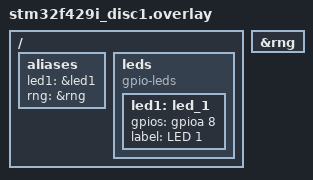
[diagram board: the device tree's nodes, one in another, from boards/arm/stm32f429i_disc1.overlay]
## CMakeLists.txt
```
cmake_minimum_required(VERSION 3.20.0)
find_package(Zephyr REQUIRED HINTS $ENV{ZEPHYR_BASE})

project(my_game_of_life)

# 1. Adiciona os arquivos fonte (.c) ao alvo 'app'

zephyr_include_directories(includes)
# 2. Diz ao CMake onde procurar o "shared_conf.h"
# (Assumindo que ele está na pasta src/ junto com os .c)

# Add all .c files inside src/
file(GLOB app_sources src/*.c)

target_sources(app PRIVATE ${app_sources})

target_include_directories(app PRIVATE src)
```

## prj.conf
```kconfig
# Habilitar Display e GPIO
CONFIG_DISPLAY=y
CONFIG_SPI=y
CONFIG_GPIO=y

# Habilitar LVGL (Biblioteca Gráfica)
#CONFIG_LVGL=y
CONFIG_LV_Z_MEM_POOL_SIZE=16384
CONFIG_LV_Z_SHELL=y
CONFIG_MAIN_STACK_SIZE=4096

# Buffer de desenho (Double Buffering recomendado para evitar flicker)
CONFIG_LV_Z_VDB_SIZE=10

# Suporte ao driver específico ILI9341 e LTDC
CONFIG_DISPLAY_LOG_LEVEL_ERR=y

# --- Geração de Números Aleatórios (Random) ---
# 1. Habilita o subsistema de entropia base
CONFIG_ENTROPY_GENERATOR=y

# 2. Habilita o driver de hardware do STM32
# (Isso vai funcionar agora graças ao seu arquivo .overlay corrigido)
CONFIG_ENTROPY_STM32_RNG=y

# 3. Diz ao Zephyr para usar o dispositivo de entropia como fonte para sys_rand_get()
# Esta é a opção que substitui as antigas CS_PRNG/SYS_RANDOM...
CONFIG_ENTROPY_DEVICE_RANDOM_GENERATOR=y

# --- Shell ---
CONFIG_SHELL=y
CONFIG_KERNEL_SHELL=y
CONFIG_SHELL_TAB_AUTOCOMPLETION=y

# --- Logging (caso use printk/LOG) ---
CONFIG_PRINTK=y
CONFIG_LOG=y
CONFIG_LOG_MODE_IMMEDIATE=y

# --- Threads / Workqueue ---
# Essencial para informações de runtime (uso de stack/pilha)
CONFIG_THREAD_MONITOR=y 
CONFIG_THREAD_NAME=y
CONFIG_SYSTEM_WORKQUEUE_STACK_SIZE=2048
CONFIG_SYSTEM_WORKQUEUE_PRIORITY=-1
# Habilita o subsistema de estatísticas de runtime
CONFIG_THREAD_RUNTIME_STATS=y 
# Permite a conversão de ciclos para milissegundos
CONFIG_SYS_CLOCK_TICKS_PER_SEC=1000

# --- UART (se usar terminal via UART) ---
CONFIG_UART_CONSOLE=y
```

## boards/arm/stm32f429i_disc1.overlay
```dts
#include <zephyr/dt-bindings/gpio/gpio.h>

/ {
	aliases {
		led1 = &led1;
        rng = &rng;
	};

	leds {
		compatible = "gpio-leds";
		led1: led_1 {
			gpios = <&gpioa 8 GPIO_ACTIVE_HIGH>; // Isso é porta 14 acho, tem que testar
			label = "LED 1";
		};
	};

};

&rng {
	status = "okay";
};
```

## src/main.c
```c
/*
 * Copyright (c) 2017 Linaro Limited
 *
 * SPDX-License-Identifier: Apache-2.0
 */

#include <zephyr/kernel.h>
#include <zephyr/device.h>
#include <zephyr/drivers/gpio.h>
#include <zephyr/sys/printk.h>
#include <zephyr/sys/__assert.h>

#include <string.h>
#include <terminal.h>

#define ZEPHYR_USER_NODE DT_PATH(zephyr_user)

/* size of stack area used by each thread */
#define STACKSIZE 1024

/* scheduling priority used by each thread */
#define PRIORITY 7

#define LED0_NODE DT_ALIAS(led0)
#define LED1_NODE DT_ALIAS(led1)

#if !DT_NODE_HAS_STATUS(LED0_NODE, okay)
#error "Unsupported board: led0 devicetree alias is not defined"
#endif


#if !DT_NODE_HAS_STATUS(LED1_NODE, okay)
#error "Unsupported board: led1 devicetree alias is not defined"
#endif

struct led {
	struct gpio_dt_spec spec;
	uint8_t num;
};

static const struct led led0 = {
	.spec = GPIO_DT_SPEC_GET_OR(LED0_NODE, gpios, {0}),
	.num = 0,
};


void blink(const struct led *led, uint32_t sleep_ms, uint32_t id)
{
	const struct gpio_dt_spec *spec = &led->spec;
	int ret;
	int cnt = 0;

	if (!device_is_ready(spec->port)) {
		printk("Error: %s device is not ready\n", spec->port->name);
		return;
	}

	ret = gpio_pin_configure_dt(spec, GPIO_OUTPUT);
	if (ret != 0) {
		printk("Error %d: failed to configure pin %d (LED '%d')\n",
			ret, spec->pin, led->num);
		return;
	}

	while (1) {
		gpio_pin_set(spec->port, spec->pin, cnt % 2);
		cnt++;

		k_msleep(sleep_ms);
	}
}

void blink0(void)
{
	blink(&led0, 200, 0);
}


K_THREAD_DEFINE(blink0_id, STACKSIZE, blink0, NULL, NULL, NULL,PRIORITY, 0, 0);
//k_thread_name_set(tid, "blink0");

int main(void)
{
    terminal_init();
    term_print("Shell ready. Try: echo, uptime, showdrop\n");

	return 0;
}
```

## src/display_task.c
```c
#include <shared_conf.h>
#include <zephyr/device.h>
#include <zephyr/drivers/display.h>
#include <string.h>

#define DISPLAY_PRIORITY 5
#define DISPLAY_STACK_SIZE 4096

static uint8_t frame_buffer[BUF_SIZE]; 

void draw_pixel(int x, int y, uint16_t color) {
    if (x < 0 || x >= SCREEN_WIDTH || y < 0 || y >= SCREEN_HEIGHT) return;
    
    int index = (y * SCREEN_WIDTH + x) * 2;
    frame_buffer[index] = color >> 8;     
    frame_buffer[index + 1] = color & 0xFF; 
}

void draw_cell(int grid_x, int grid_y, uint16_t color) {
    int start_x = grid_x * CELL_SIZE;
    int start_y = grid_y * CELL_SIZE;

    for (int y = 0; y < CELL_SIZE; y++) {
        for (int x = 0; x < CELL_SIZE; x++) {
            if (x < CELL_SIZE - 1 && y < CELL_SIZE - 1) {
                draw_pixel(start_x + x, start_y + y, color);
            }
        }
    }
}

// Função da Thread
void display_entry_point(void *p1, void *p2, void *p3) {
    const struct device *display_dev = DEVICE_DT_GET(DT_CHOSEN(zephyr_display));

    if (!device_is_ready(display_dev)) return;
    
    display_blanking_off(display_dev);

    struct display_buffer_descriptor desc;
    desc.buf_size = BUF_SIZE;
    desc.width = SCREEN_WIDTH;
    desc.height = SCREEN_HEIGHT;
    desc.pitch = SCREEN_WIDTH;

    while (1) {
        k_mutex_lock(&game_mutex, K_FOREVER);
        
        for (int y = 0; y < GRID_H; y++) {
            for (int x = 0; x < GRID_W; x++) {
                if (grid[y][x] == 1) {
                    draw_cell(x, y, COLOR_ALIVE);
                }else{
                    draw_cell(x, y, 0x0000);
                }
            }
        }
        
        k_mutex_unlock(&game_mutex);
        display_write(display_dev, 0, 0, &desc, frame_buffer);

        // Pequeno delay para evitar starvation
        k_sleep(K_MSEC(10)); 
    }
}

// Define e inicia a thread automaticamente no boot
K_THREAD_DEFINE(display_tid, DISPLAY_STACK_SIZE, display_entry_point, NULL, NULL, NULL,
                DISPLAY_PRIORITY, 0, 0);
```

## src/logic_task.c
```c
#include <shared_conf.h>
#include <zephyr/random/random.h>
#include <string.h>

// Definição das prioridades e stack
#define LOGIC_PRIORITY -1 // Alta prioridade 
#define LOGIC_STACK_SIZE 1024
#define LOGIC_PERIOD_MS 200
//#define EVENT_RESET_GRID_BIT (1 << 0)

uint8_t grid[GRID_H][GRID_W];
struct k_mutex game_mutex;
struct k_event game_events;
static uint8_t next_grid[GRID_H][GRID_W];
static uint32_t alive_count = 0;

void init_grid() {
    for (int y = 0; y < GRID_H; y++) {
        for (int x = 0; x < GRID_W; x++) {
            grid[y][x] = (sys_rand32_get() % 2); 
        }
    }
}

int count_neighbors(int x, int y) {
    int sum = 0;
    for (int i = -1; i < 2; i++) {
        for (int j = -1; j < 2; j++) {
            if(i == 0 && j == 0) continue; 
            int col = (x + j + GRID_W) % GRID_W;
            int row = (y + i + GRID_H) % GRID_H;
            sum += grid[row][col];
        }
    }
    return sum;
}

// --- Contagem e Status ---
uint32_t gol_get_alive_count() {
    return alive_count;
}

void compute_next_generation() {
    uint32_t count = 0;

    for (int y = 0; y < GRID_H; y++) {
        for (int x = 0; x < GRID_W; x++) {
            int state = grid[y][x];
            int neighbors = count_neighbors(x, y);

            if (state == 0 && neighbors == 3) {
                next_grid[y][x] = 1; 
            } else if (state == 1 && (neighbors < 2 || neighbors > 3)) {
                next_grid[y][x] = 0; 
            } else {
                next_grid[y][x] = state; 
            }
        }
    }

    // BLOQUEIA para atualizar o grid oficial
    k_mutex_lock(&game_mutex, K_FOREVER);
    memcpy(grid, next_grid, sizeof(grid));

    // Calcula a contagem de vivos após a atualização (aproveitando o mutex)
    for (int y = 0; y < GRID_H; y++) {
        for (int x = 0; x < GRID_W; x++) {
            if (grid[y][x] == 1) {
                count++;
            }
        }
    }

    alive_count = count;

    k_mutex_unlock(&game_mutex);
}

void logic_entry_point(void *p1, void *p2, void *p3) {
    k_mutex_init(&game_mutex); // Inicializa o mutex uma vez
    k_event_init(&game_events);

    k_mutex_lock(&game_mutex, K_FOREVER);
    init_grid();
    k_mutex_unlock(&game_mutex);

    int64_t next_run_time = k_uptime_get();

    while (1) {
        //compute_next_generation();

        next_run_time += LOGIC_PERIOD_MS;

        uint32_t events = k_event_wait(&game_events, EVENT_RESET_GRID_BIT, true, K_MSEC(100));
        if (events & EVENT_RESET_GRID_BIT) {
            // Se recebeu o evento: Reseta
            k_mutex_lock(&game_mutex, K_FOREVER);
            init_grid();
            k_mutex_unlock(&game_mutex);
        } else {
            compute_next_generation();
        }

        int64_t now = k_uptime_get();
        int32_t remaining = (int32_t)(next_run_time - now);

        if (remaining > 0) {
            k_sleep(K_MSEC(remaining));
            
        } else {
            //printk("ALERTA: Prazo perdido! Atraso de %d ms\n", remaining);
            next_run_time = now; 
        }
    }
}

// Define e inicia a thread automaticamente no boot
K_THREAD_DEFINE(logic_tid, LOGIC_STACK_SIZE, logic_entry_point, NULL, NULL, NULL,
                LOGIC_PRIORITY, 0, 0);
```

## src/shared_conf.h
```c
#ifndef SHARED_CONF_H
#define SHARED_CONF_H

#include <zephyr/kernel.h>
#include <stdint.h>

/* Configurações do Display */
#define SCREEN_WIDTH 240
#define SCREEN_HEIGHT 320
#define BUF_SIZE (SCREEN_WIDTH * SCREEN_HEIGHT * 2)

/* Configurações do Game of Life */
#define CELL_SIZE 10 
#define GRID_W (SCREEN_WIDTH / CELL_SIZE)
#define GRID_H (SCREEN_HEIGHT / CELL_SIZE)

/* Cores */
#define COLOR_ALIVE 0xFFFF
#define COLOR_DEAD  0x0000

/* Variáveis Compartilhadas */
/* O grid é definido na logic_task.c, mas o display precisa ler */
extern uint8_t grid[GRID_H][GRID_W];

/* Mutex para evitar que o desenho leia enquanto a lógica escreve */
extern struct k_mutex game_mutex;

extern struct k_event game_events;
#define EVENT_RESET_GRID_BIT  (1 << 0)

#endif
```

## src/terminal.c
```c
#include <zephyr/kernel.h>
#include <zephyr/shell/shell.h>
#include <zephyr/sys/util.h>
#include <zephyr/kernel/thread.h>
#include <zephyr/sys/printk.h>
#include <zephyr/sys/util.h>
#include <shared_conf.h> 

#include <stdarg.h>
#include <string.h>
#include <stdint.h>
#include <stddef.h>

/* ---------------- Configuration ---------------- */

#define PRINT_MSG_MAXLEN 256
#define PRINT_MSGQ_DEPTH 32

/* * DEFINIÇÃO DE PRIORIDADE CRÍTICA:
 * Lógica: -1 (Máxima)
 * Terminal: 4 (Alta - Interrompe o display para imprimir rápido)
 * Display: 5 (Média - Roda quando ninguém mais precisa)
 */
#define TERMINAL_PRIORITY 4 
#define TERMINAL_STACK_SIZE 1024

/* ---------------- Internal Types ---------------- */

struct print_msg {
    uint32_t len;
    char payload[PRINT_MSG_MAXLEN];
};

/* ---------------- Internal State ---------------- */

K_MSGQ_DEFINE(print_msgq, sizeof(struct print_msg), PRINT_MSGQ_DEPTH, 4);

static atomic_t dropped_msgs = ATOMIC_INIT(0);

K_MUTEX_DEFINE(print_mutex); 

/* REMOVIDO: k_work e k_timer (causadores do travamento) */

/* ---------------- Internal Forward Decls ---------------- */
/* A função handler agora é o loop da thread dedicada */
void terminal_thread_entry(void *p1, void *p2, void *p3);

/* ---------------- Public Print API ---------------- */

void term_print(const char *fmt, ...)
{
    struct print_msg msg;
    va_list ap;
    int needed;

    va_start(ap, fmt);
    needed = vsnprintf(msg.payload, sizeof(msg.payload), fmt, ap);
    va_end(ap);

    if (needed < 0) {
        return;
    }

    if ((size_t)needed >= sizeof(msg.payload)) {
        msg.len = sizeof(msg.payload) - 1;
        msg.payload[msg.len] = '\0';
    } else {
        msg.len = needed;
    }

    /* Coloca na fila. A thread dedicada acordará imediatamente se tiver prioridade. */
    if (k_msgq_put(&print_msgq, &msg, K_NO_WAIT) != 0) {
        atomic_inc(&dropped_msgs);
        return;
    }
}

/* ---------------- Thread Logic (Substitui Work/Timer) ---------------- */

void terminal_thread_entry(void *p1, void *p2, void *p3)
{
    struct print_msg msg;

    while (1) {
        /* * K_FOREVER: A thread fica suspensa aqui consumindo 0% de CPU 
         * até que k_msgq_put seja chamado em term_print.
         */
        if (k_msgq_get(&print_msgq, &msg, K_FOREVER) == 0) {
            
            k_mutex_lock(&print_mutex, K_FOREVER);
            // Saída real para o console
            printk("%.*s", msg.len, msg.payload);
            k_mutex_unlock(&print_mutex);
        }
    }
}

/* Inicializa a thread automaticamente com Prioridade 4 */
K_THREAD_DEFINE(terminal_tid, TERMINAL_STACK_SIZE, terminal_thread_entry, NULL, NULL, NULL,
                TERMINAL_PRIORITY, 0, 0);


/* ---------------- Auxiliary Funcs (Threads Info) ---------------- */

static void print_single_thread(const struct k_thread *thread, void *dummy)
{
    static char state_buf[20]; 
    struct k_thread *t = (struct k_thread *)thread; 
    size_t unused_stack_size;
    uint32_t total_stack_size = 0;

    const char *thread_name = k_thread_name_get(t); 
    const char *state_str;

    state_str = k_thread_state_str(t, state_buf, sizeof(state_buf));

    if (t->stack_info.size > 0) {
        total_stack_size = t->stack_info.size;
    }

    if (k_thread_stack_space_get(t, &unused_stack_size) == 0) {
        term_print("  %-16s (0x%p)", thread_name ? thread_name : "N/A", (void *)t);
        term_print("    Estado: %s | Prio: %d", state_str, t->base.prio); 
        if (total_stack_size > 0) {
            uint32_t used_stack = total_stack_size - (uint32_t)unused_stack_size;
            term_print("    Stack Total: %u | Usado: %u | Livre: %u\n",
                    total_stack_size, used_stack, (uint32_t)unused_stack_size);
        } else {
            term_print("    Stack Info: Não disponível ou thread de kernel.\n");
        }
    } else {
        term_print("  %-16s (0x%p) | Estado: %s | Prio: %d | Stack Info: Desconhecida\n", 
                thread_name ? thread_name : "N/A", (void *)t, state_str, t->base.prio);
    }
}

static int cmd_golinfo(const struct shell *sh, size_t argc, char **argv)
{
    ARG_UNUSED(sh);
    ARG_UNUSED(argc);
    ARG_UNUSED(argv);

    uint32_t alive = gol_get_alive_count();
    uint32_t total = GRID_H * GRID_W;
    
    uint64_t density_x10 = (uint64_t)alive * 1000ULL / total;
    uint32_t density_int = (uint32_t)(density_x10 / 10);
    uint32_t density_dec = (uint32_t)(density_x10 % 10);
    
    term_print("--- Conway's GoL Status (Somente Dados do Jogo) ---\n");
    term_print("Células Vivas Atuais: %u / %u\n", alive, total);
    term_print("Densidade Média: %u.%u %%\n", density_int, density_dec);
    term_print("-------------------------------------------------\n");

    return 0;
}

/* ---------------- Shell Commands ---------------- */

static int cmd_echo(const struct shell *sh, size_t argc, char **argv)
{
    ARG_UNUSED(sh);
    if (argc < 2) {
        term_print("Usage: echo <text>\n");
        return 0;
    }
    for (size_t i = 1; i < argc; i++) {
        term_print("%s%s", argv[i], (i + 1 < argc) ? " " : "\n");
    }
    return 0;
}

static int cmd_uptime(const struct shell *sh, size_t argc, char **argv)
{
    ARG_UNUSED(sh);
    term_print("Uptime: %u ms\n", k_uptime_get_32());
    return 0;
}

static int cmd_showdrop(const struct shell *sh, size_t argc, char **argv)
{
    ARG_UNUSED(sh);
    term_print("Dropped messages: %d\n", atomic_get(&dropped_msgs));
    return 0;
}

static int cmd_restart(const struct shell *sh, size_t argc, char **argv)
{
    ARG_UNUSED(sh);
    k_event_post(&game_events, EVENT_RESET_GRID_BIT);
    return 0;
}

static int cmd_sysinfo(const struct shell *sh, size_t argc, char **argv)
{
    ARG_UNUSED(sh);
    term_print("--- Informações de Tarefas Instaladas e Runtime ---\n");
    k_thread_foreach(print_single_thread, NULL);
    term_print("---------------------------------------------------\n");
    return 0;
}

/* Register commands */
SHELL_CMD_REGISTER(echo, NULL, "Echo back text using terminal", cmd_echo);
SHELL_CMD_REGISTER(uptime, NULL, "Show uptime (ms)", cmd_uptime);
SHELL_CMD_REGISTER(showdrop, NULL, "Dropped terminal messages", cmd_showdrop);
SHELL_CMD_REGISTER(restart, NULL, "Restart the Game", cmd_restart);
SHELL_CMD_REGISTER(sysinfo, NULL, "Mostra informações das tarefas (threads) e runtime.", cmd_sysinfo);
SHELL_CMD_REGISTER(golinfo, NULL, "Mostra status e runtime da tarefa GoL (Game of Life).", cmd_golinfo);

/* ---------------- Public Initialization ---------------- */

void terminal_init(void)
{
    /* A thread já inicia via K_THREAD_DEFINE, apenas notificamos o boot */
    term_print("Terminal initialized (Priority %d).\n", TERMINAL_PRIORITY);
}
```
